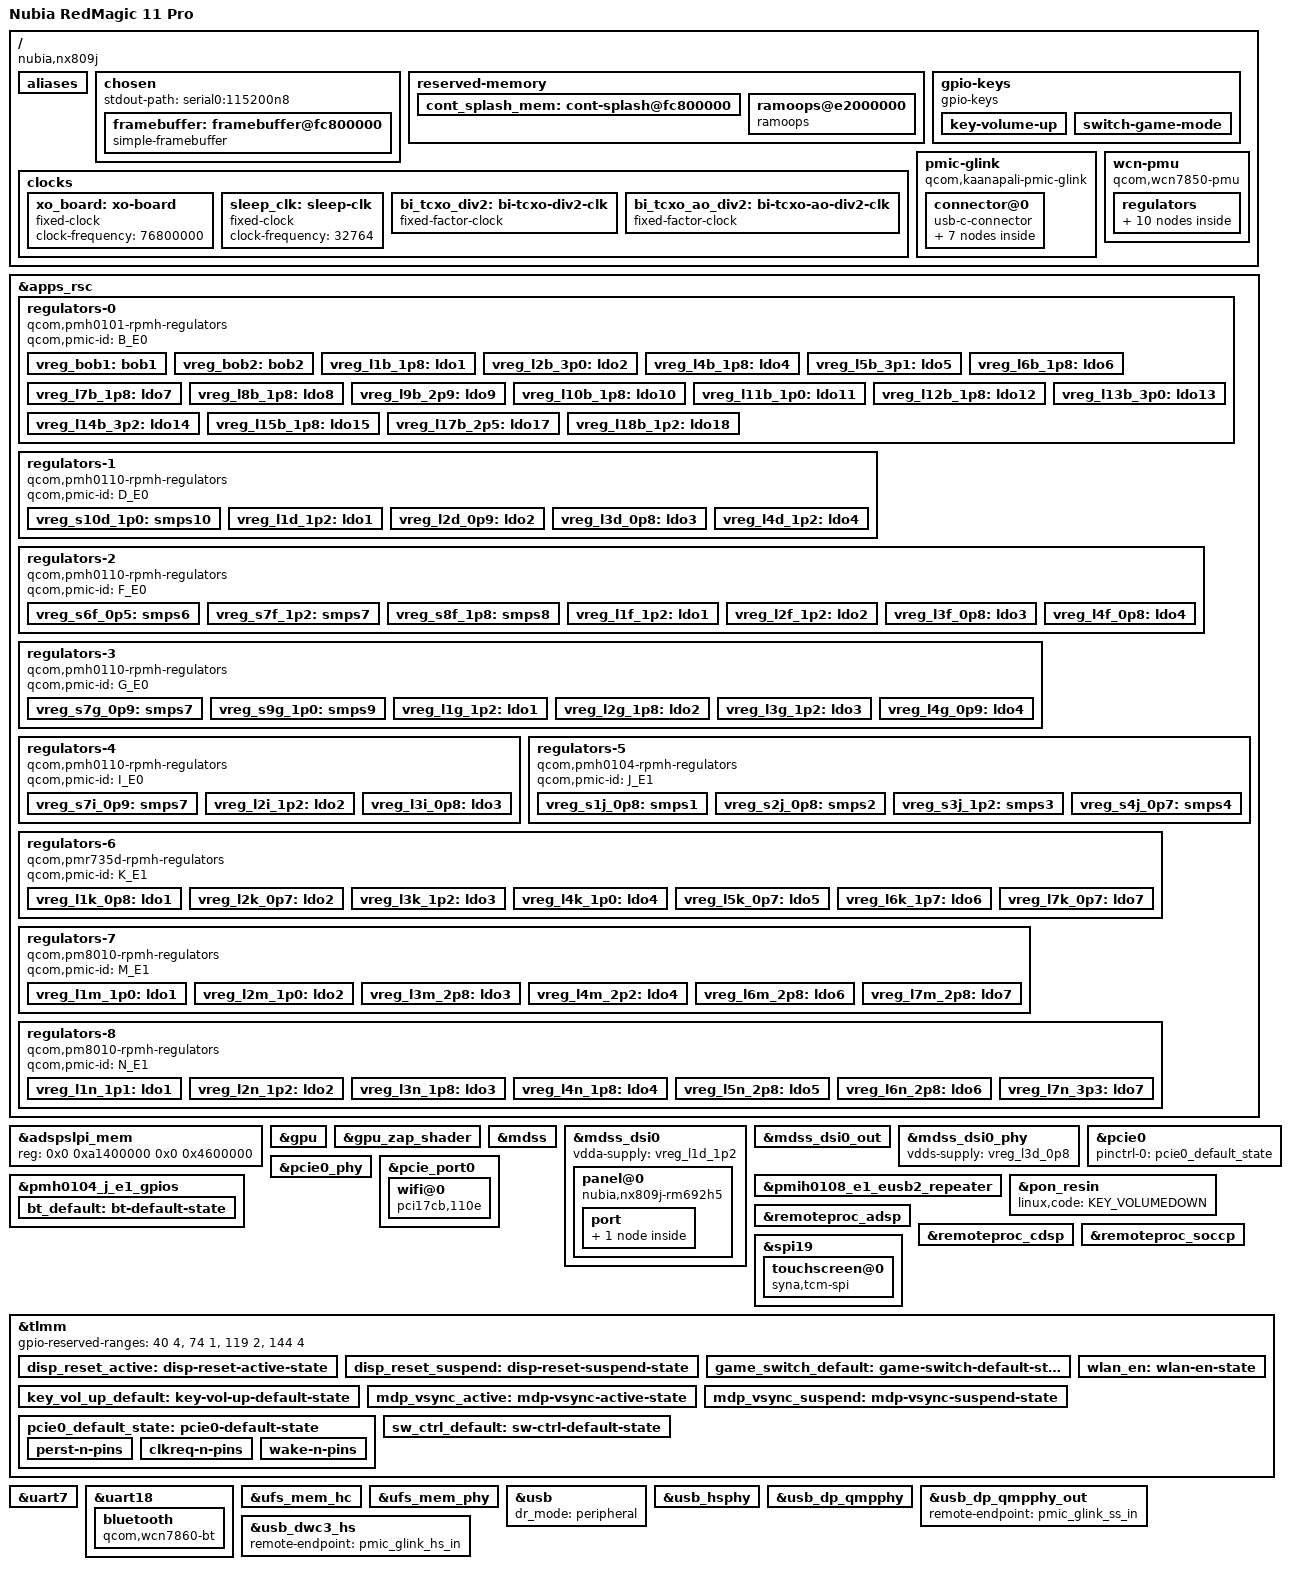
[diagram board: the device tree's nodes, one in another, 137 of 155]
// SPDX-License-Identifier: BSD-3-Clause
/*
 * Nubia RedMagic 11 Pro (NX809J), based on kaanapali-qrd.dts
 *
 * Copyright (c) Qualcomm Technologies, Inc. and/or its subsidiaries.
 */

/dts-v1/;

#include <dt-bindings/gpio/gpio.h>
#include <dt-bindings/input/linux-event-codes.h>
#include <dt-bindings/leds/common.h>
#include <dt-bindings/regulator/qcom,rpmh-regulator.h>
#include "kaanapali.dtsi"

#include "pm8010-kaanapali.dtsi"     /* SPMI1: SID-12/13   */
#include "pmd8028-kaanapali.dtsi"    /* SPMI1: SID-4       */
#include "pmh0101.dtsi"              /* SPMI0: SID-1       */
#include "pmh0104-kaanapali.dtsi"    /* SPMI1: SID-9       */
#include "pmh0110-kaanapali.dtsi"    /* SPMI0: SID-3/5/6/8 */
#include "pmih0108-kaanapali.dtsi"   /* SPMI1: SID-7       */
#include "pmk8850.dtsi"              /* SPMI0: SID-0       */
#include "pmr735d-kaanapali.dtsi"    /* SPMI1: SID-10      */

/ {
	model = "Nubia RedMagic 11 Pro";
	compatible = "nubia,nx809j", "qcom,kaanapali";
	chassis-type = "handset";

	/* Needed by the stock ABL to pick this DTB (soc 660 v2.0, MTP board) */
	qcom,msm-id = <660 0x20000>;
	qcom,board-id = <8 0>;

	aliases {
		serial0 = &uart7;
		serial1 = &uart18;
	};

	chosen {
		#address-cells = <2>;
		#size-cells = <2>;
		ranges;

		stdout-path = "serial0:115200n8";

		/* Bootloader splash, left running by ABL (BF375 RM692H5, DSC cmd mode) */
		framebuffer: framebuffer@fc800000 {
			compatible = "simple-framebuffer";
			reg = <0x0 0xfc800000 0x0 (1216 * 2688 * 4)>;
			width = <1216>;
			height = <2688>;
			stride = <(1216 * 4)>;
			format = "a8r8g8b8";
		};
	};

	reserved-memory {
		#address-cells = <2>;
		#size-cells = <2>;
		ranges;

		cont_splash_mem: cont-splash@fc800000 {
			reg = <0x0 0xfc800000 0x0 0x2b00000>;
			no-map;
		};

		/*
		 * Same layout as downstream (incl. write-combine mem-type 0), so
		 * Android shows our log in /sys/fs/pstore. A cached mapping would
		 * lose the log in the CPU caches on a hard reset.
		 */
		ramoops@e2000000 {
			compatible = "ramoops";
			reg = <0x0 0xe2000000 0x0 0x200000>;
			console-size = <0x200000>;
			mem-type = <0>;
		};
	};

	clocks {
		xo_board: xo-board {
			compatible = "fixed-clock";
			clock-frequency = <76800000>;
			#clock-cells = <0>;
		};

		sleep_clk: sleep-clk {
			compatible = "fixed-clock";
			clock-frequency = <32764>;
			#clock-cells = <0>;
		};

		bi_tcxo_div2: bi-tcxo-div2-clk {
			compatible = "fixed-factor-clock";
			#clock-cells = <0>;

			clocks = <&rpmhcc RPMH_CXO_CLK>;
			clock-mult = <1>;
			clock-div = <2>;
		};

		bi_tcxo_ao_div2: bi-tcxo-ao-div2-clk {
			compatible = "fixed-factor-clock";
			#clock-cells = <0>;

			clocks = <&rpmhcc RPMH_CXO_CLK_A>;
			clock-mult = <1>;
			clock-div = <2>;
		};
	};

	gpio-keys {
		compatible = "gpio-keys";

		pinctrl-0 = <&key_vol_up_default>, <&game_switch_default>;
		pinctrl-names = "default";

		key-volume-up {
			label = "Volume Up";
			linux,code = <KEY_VOLUMEUP>;
			gpios = <&tlmm 101 GPIO_ACTIVE_LOW>;
			debounce-interval = <15>;
			linux,can-disable;
			wakeup-source;
		};

		/*
		 * Game mode slider. Downstream reads GPIO 97 (and its complement
		 * on GPIO 174) and reports it as SW_PEN_INSERTED for lack of a
		 * better code; kept the same for now.
		 */
		switch-game-mode {
			label = "Game Mode Switch";
			linux,input-type = <EV_SW>;
			linux,code = <SW_PEN_INSERTED>;
			gpios = <&tlmm 97 GPIO_ACTIVE_HIGH>;
			debounce-interval = <30>;
		};
	};

	pmic-glink {
		compatible = "qcom,kaanapali-pmic-glink",
			     "qcom,pmic-glink";
		#address-cells = <1>;
		#size-cells = <0>;

		connector@0 {
			compatible = "usb-c-connector";
			reg = <0>;

			power-role = "dual";
			data-role = "dual";

			ports {
				#address-cells = <1>;
				#size-cells = <0>;

				port@0 {
					reg = <0>;

					pmic_glink_hs_in: endpoint {
						remote-endpoint = <&usb_dwc3_hs>;
					};
				};

				port@1 {
					reg = <1>;

					pmic_glink_ss_in: endpoint {
						remote-endpoint = <&usb_dp_qmpphy_out>;
					};
				};

				port@2 {
					reg = <2>;

					pmic_glink_sbu: endpoint {
					};
				};
			};
		};
	};

	/*
	 * The Wi-Fi/BT combo is Qualcomm's "peach" (PCI 17cb:110e), not the
	 * MTP's WCN7850, but it is wired the same way: same enable GPIOs,
	 * supplies and RF clock (downstream qcom,cnss-peach and bt_peach).
	 */
	wcn-pmu {
		compatible = "qcom,wcn7850-pmu";

		pinctrl-0 = <&bt_default>, <&sw_ctrl_default>, <&wlan_en>;
		pinctrl-names = "default";

		bt-enable-gpios = <&pmh0104_j_e1_gpios 5 GPIO_ACTIVE_HIGH>;
		wlan-enable-gpios = <&tlmm 16 GPIO_ACTIVE_HIGH>;

		vdd-supply = <&vreg_s2j_0p8>;
		vddio-supply = <&vreg_l2g_1p8>;
		vddio1p2-supply = <&vreg_l3g_1p2>;
		vddaon-supply = <&vreg_s7g_0p9>;
		vdddig-supply = <&vreg_s1j_0p8>;
		vddrfa1p2-supply = <&vreg_s7f_1p2>;
		vddrfa1p8-supply = <&vreg_s8f_1p8>;

		clocks = <&rpmhcc RPMH_RF_CLK1>;

		regulators {
			vreg_pmu_rfa_cmn: ldo0 {
				regulator-name = "vreg_pmu_rfa_cmn";
			};

			vreg_pmu_aon_0p59: ldo1 {
				regulator-name = "vreg_pmu_aon_0p59";
			};

			vreg_pmu_wlcx_0p8: ldo2 {
				regulator-name = "vreg_pmu_wlcx_0p8";
			};

			vreg_pmu_wlmx_0p85: ldo3 {
				regulator-name = "vreg_pmu_wlmx_0p85";
			};

			vreg_pmu_btcmx_0p85: ldo4 {
				regulator-name = "vreg_pmu_btcmx_0p85";
			};

			vreg_pmu_rfa_0p8: ldo5 {
				regulator-name = "vreg_pmu_rfa_0p8";
			};

			vreg_pmu_rfa_1p2: ldo6 {
				regulator-name = "vreg_pmu_rfa_1p2";
			};

			vreg_pmu_rfa_1p8: ldo7 {
				regulator-name = "vreg_pmu_rfa_1p8";
			};

			vreg_pmu_pcie_0p9: ldo8 {
				regulator-name = "vreg_pmu_pcie_0p9";
			};

			vreg_pmu_pcie_1p8: ldo9 {
				regulator-name = "vreg_pmu_pcie_1p8";
			};
		};
	};
};

&apps_rsc {
	regulators-0 {
		compatible = "qcom,pmh0101-rpmh-regulators";
		qcom,pmic-id = "B_E0";

		vreg_bob1: bob1 {
			regulator-name = "vreg_bob1";
			regulator-min-microvolt = <3008000>;
			regulator-max-microvolt = <4000000>;
			regulator-initial-mode = <RPMH_REGULATOR_MODE_HPM>;
		};

		vreg_bob2: bob2 {
			regulator-name = "vreg_bob2";
			regulator-min-microvolt = <2704000>;
			regulator-max-microvolt = <3552000>;
			regulator-initial-mode = <RPMH_REGULATOR_MODE_HPM>;
		};

		vreg_l1b_1p8: ldo1 {
			regulator-name = "vreg_l1b_1p8";
			regulator-min-microvolt = <1800000>;
			regulator-max-microvolt = <1800000>;
			regulator-initial-mode = <RPMH_REGULATOR_MODE_AUTO>;
			regulator-allow-set-load;
			regulator-allowed-modes = <RPMH_REGULATOR_MODE_LPM
						   RPMH_REGULATOR_MODE_AUTO>;
		};

		vreg_l2b_3p0: ldo2 {
			regulator-name = "vreg_l2b_3p0";
			regulator-min-microvolt = <3008000>;
			regulator-max-microvolt = <3048000>;
			regulator-initial-mode = <RPMH_REGULATOR_MODE_AUTO>;
			regulator-allow-set-load;
			regulator-allowed-modes = <RPMH_REGULATOR_MODE_LPM
						   RPMH_REGULATOR_MODE_AUTO>;
		};

		vreg_l4b_1p8: ldo4 {
			regulator-name = "vreg_l4b_1p8";
			regulator-min-microvolt = <1800000>;
			regulator-max-microvolt = <1800000>;
			regulator-initial-mode = <RPMH_REGULATOR_MODE_AUTO>;
			regulator-allow-set-load;
			regulator-allowed-modes = <RPMH_REGULATOR_MODE_LPM
						   RPMH_REGULATOR_MODE_AUTO>;
		};

		vreg_l5b_3p1: ldo5 {
			regulator-name = "vreg_l5b_3p1";
			regulator-min-microvolt = <3100000>;
			regulator-max-microvolt = <3148000>;
			regulator-initial-mode = <RPMH_REGULATOR_MODE_AUTO>;
			regulator-allow-set-load;
			regulator-allowed-modes = <RPMH_REGULATOR_MODE_LPM
						   RPMH_REGULATOR_MODE_AUTO>;
		};

		vreg_l6b_1p8: ldo6 {
			regulator-name = "vreg_l6b_1p8";
			regulator-min-microvolt = <1800000>;
			regulator-max-microvolt = <3008000>;
			regulator-initial-mode = <RPMH_REGULATOR_MODE_AUTO>;
			regulator-allow-set-load;
			regulator-allowed-modes = <RPMH_REGULATOR_MODE_LPM
						   RPMH_REGULATOR_MODE_AUTO>;
		};

		vreg_l7b_1p8: ldo7 {
			regulator-name = "vreg_l7b_1p8";
			regulator-min-microvolt = <1800000>;
			regulator-max-microvolt = <3008000>;
			regulator-initial-mode = <RPMH_REGULATOR_MODE_AUTO>;
			regulator-allow-set-load;
			regulator-allowed-modes = <RPMH_REGULATOR_MODE_LPM
						   RPMH_REGULATOR_MODE_AUTO>;
		};

		vreg_l8b_1p8: ldo8 {
			regulator-name = "vreg_l8b_1p8";
			regulator-min-microvolt = <1800000>;
			regulator-max-microvolt = <3300000>;
			regulator-initial-mode = <RPMH_REGULATOR_MODE_AUTO>;
			regulator-allow-set-load;
			regulator-allowed-modes = <RPMH_REGULATOR_MODE_LPM
						   RPMH_REGULATOR_MODE_AUTO>;
		};

		vreg_l9b_2p9: ldo9 {
			regulator-name = "vreg_l9b_2p9";
			regulator-min-microvolt = <2960000>;
			regulator-max-microvolt = <3008000>;
			regulator-initial-mode = <RPMH_REGULATOR_MODE_HPM>;
			regulator-allow-set-load;
			regulator-allowed-modes = <RPMH_REGULATOR_MODE_LPM
						   RPMH_REGULATOR_MODE_HPM>;
		};

		vreg_l10b_1p8: ldo10 {
			regulator-name = "vreg_l10b_1p8";
			regulator-min-microvolt = <1800000>;
			regulator-max-microvolt = <1800000>;
			regulator-initial-mode = <RPMH_REGULATOR_MODE_AUTO>;
			regulator-allow-set-load;
			regulator-allowed-modes = <RPMH_REGULATOR_MODE_LPM
						   RPMH_REGULATOR_MODE_AUTO>;
		};

		vreg_l11b_1p0: ldo11 {
			regulator-name = "vreg_l11b_1p0";
			regulator-min-microvolt = <1000000>;
			regulator-max-microvolt = <1292000>;
			regulator-initial-mode = <RPMH_REGULATOR_MODE_AUTO>;
			regulator-allow-set-load;
			regulator-allowed-modes = <RPMH_REGULATOR_MODE_LPM
						   RPMH_REGULATOR_MODE_AUTO>;
		};

		vreg_l12b_1p8: ldo12 {
			regulator-name = "vreg_l12b_1p8";
			regulator-min-microvolt = <1200000>;
			regulator-max-microvolt = <1800000>;
			regulator-initial-mode = <RPMH_REGULATOR_MODE_AUTO>;
			regulator-allow-set-load;
			regulator-allowed-modes = <RPMH_REGULATOR_MODE_LPM
						   RPMH_REGULATOR_MODE_AUTO>;
		};

		vreg_l13b_3p0: ldo13 {
			regulator-name = "vreg_l13b_3p0";
			regulator-min-microvolt = <3000000>;
			regulator-max-microvolt = <3000000>;
			regulator-initial-mode = <RPMH_REGULATOR_MODE_AUTO>;
			regulator-allow-set-load;
			regulator-allowed-modes = <RPMH_REGULATOR_MODE_LPM
						   RPMH_REGULATOR_MODE_AUTO>;
		};

		vreg_l14b_3p2: ldo14 {
			regulator-name = "vreg_l14b_3p2";
			regulator-min-microvolt = <3200000>;
			regulator-max-microvolt = <3200000>;
			regulator-initial-mode = <RPMH_REGULATOR_MODE_AUTO>;
			regulator-allow-set-load;
			regulator-allowed-modes = <RPMH_REGULATOR_MODE_LPM
						   RPMH_REGULATOR_MODE_AUTO>;
		};

		vreg_l15b_1p8: ldo15 {
			regulator-name = "vreg_l15b_1p8";
			regulator-min-microvolt = <1800000>;
			regulator-max-microvolt = <1800000>;
			regulator-initial-mode = <RPMH_REGULATOR_MODE_AUTO>;
			regulator-allow-set-load;
			regulator-allowed-modes = <RPMH_REGULATOR_MODE_LPM
						   RPMH_REGULATOR_MODE_AUTO>;
		};

		vreg_l17b_2p5: ldo17 {
			regulator-name = "vreg_l17b_2p5";
			regulator-min-microvolt = <2504000>;
			regulator-max-microvolt = <2504000>;
			regulator-initial-mode = <RPMH_REGULATOR_MODE_HPM>;
			regulator-allow-set-load;
			regulator-allowed-modes = <RPMH_REGULATOR_MODE_LPM
						   RPMH_REGULATOR_MODE_HPM>;
		};

		vreg_l18b_1p2: ldo18 {
			regulator-name = "vreg_l18b_1p2";
			regulator-min-microvolt = <1200000>;
			regulator-max-microvolt = <1200000>;
			regulator-initial-mode = <RPMH_REGULATOR_MODE_AUTO>;
			regulator-allow-set-load;
			regulator-allowed-modes = <RPMH_REGULATOR_MODE_LPM
						   RPMH_REGULATOR_MODE_AUTO>;
		};
	};

	regulators-1 {
		compatible = "qcom,pmh0110-rpmh-regulators";
		qcom,pmic-id = "D_E0";

		vreg_s10d_1p0: smps10 {
			regulator-name = "vreg_s10d_1p0";
			regulator-min-microvolt = <1000000>;
			regulator-max-microvolt = <1100000>;
			regulator-initial-mode = <RPMH_REGULATOR_MODE_HPM>;
		};

		vreg_l1d_1p2: ldo1 {
			regulator-name = "vreg_l1d_1p2";
			regulator-min-microvolt = <1200000>;
			regulator-max-microvolt = <1256000>;
			regulator-initial-mode = <RPMH_REGULATOR_MODE_AUTO>;
			regulator-allow-set-load;
			regulator-allowed-modes = <RPMH_REGULATOR_MODE_LPM
						   RPMH_REGULATOR_MODE_AUTO>;
		};

		vreg_l2d_0p9: ldo2 {
			regulator-name = "vreg_l2d_0p9";
			regulator-min-microvolt = <912000>;
			regulator-max-microvolt = <958000>;
			regulator-initial-mode = <RPMH_REGULATOR_MODE_AUTO>;
			regulator-allow-set-load;
			regulator-allowed-modes = <RPMH_REGULATOR_MODE_LPM
						   RPMH_REGULATOR_MODE_AUTO>;
		};

		vreg_l3d_0p8: ldo3 {
			regulator-name = "vreg_l3d_0p8";
			regulator-min-microvolt = <880000>;
			regulator-max-microvolt = <880000>;
			regulator-initial-mode = <RPMH_REGULATOR_MODE_AUTO>;
			regulator-allow-set-load;
			regulator-allowed-modes = <RPMH_REGULATOR_MODE_LPM
						   RPMH_REGULATOR_MODE_AUTO>;
		};

		vreg_l4d_1p2: ldo4 {
			regulator-name = "vreg_l4d_1p2";
			regulator-min-microvolt = <1200000>;
			regulator-max-microvolt = <1200000>;
			regulator-initial-mode = <RPMH_REGULATOR_MODE_AUTO>;
			regulator-allow-set-load;
			regulator-allowed-modes = <RPMH_REGULATOR_MODE_LPM
						   RPMH_REGULATOR_MODE_AUTO>;
		};
	};

	regulators-2 {
		compatible = "qcom,pmh0110-rpmh-regulators";
		qcom,pmic-id = "F_E0";

		vreg_s6f_0p5: smps6 {
			regulator-name = "vreg_s6f_0p5";
			regulator-min-microvolt = <300000>;
			regulator-max-microvolt = <570000>;
			regulator-initial-mode = <RPMH_REGULATOR_MODE_HPM>;
		};

		/*
		 * S7F/S8F feed the Wi-Fi/BT chip's RF (and PCIe) rails. As for
		 * S1J/S2J, nothing sets their voltage: use downstream cnss2's
		 * vdd-wlan-rfa2/rfa1 floors, 1.328 V and 1.876 V.
		 */
		vreg_s7f_1p2: smps7 {
			regulator-name = "vreg_s7f_1p2";
			regulator-min-microvolt = <1328000>;
			regulator-max-microvolt = <1372000>;
			regulator-initial-mode = <RPMH_REGULATOR_MODE_HPM>;
		};

		vreg_s8f_1p8: smps8 {
			regulator-name = "vreg_s8f_1p8";
			regulator-min-microvolt = <1876000>;
			regulator-max-microvolt = <2000000>;
			regulator-initial-mode = <RPMH_REGULATOR_MODE_HPM>;
		};

		vreg_l1f_1p2: ldo1 {
			regulator-name = "vreg_l1f_1p2";
			regulator-min-microvolt = <1200000>;
			regulator-max-microvolt = <1200000>;
			regulator-initial-mode = <RPMH_REGULATOR_MODE_AUTO>;
			regulator-allow-set-load;
			regulator-allowed-modes = <RPMH_REGULATOR_MODE_LPM
						   RPMH_REGULATOR_MODE_AUTO>;
		};

		vreg_l2f_1p2: ldo2 {
			regulator-name = "vreg_l2f_1p2";
			regulator-min-microvolt = <1200000>;
			regulator-max-microvolt = <1200000>;
			regulator-initial-mode = <RPMH_REGULATOR_MODE_AUTO>;
			regulator-allow-set-load;
			regulator-allowed-modes = <RPMH_REGULATOR_MODE_LPM
						   RPMH_REGULATOR_MODE_AUTO>;
		};

		vreg_l3f_0p8: ldo3 {
			regulator-name = "vreg_l3f_0p8";
			regulator-min-microvolt = <880000>;
			regulator-max-microvolt = <936000>;
			regulator-initial-mode = <RPMH_REGULATOR_MODE_AUTO>;
			regulator-allow-set-load;
			regulator-allowed-modes = <RPMH_REGULATOR_MODE_LPM
						   RPMH_REGULATOR_MODE_AUTO>;
		};

		vreg_l4f_0p8: ldo4 {
			regulator-name = "vreg_l4f_0p8";
			regulator-min-microvolt = <880000>;
			regulator-max-microvolt = <912000>;
			regulator-initial-mode = <RPMH_REGULATOR_MODE_AUTO>;
			regulator-allow-set-load;
			regulator-allowed-modes = <RPMH_REGULATOR_MODE_LPM
						   RPMH_REGULATOR_MODE_AUTO>;
		};
	};

	regulators-3 {
		compatible = "qcom,pmh0110-rpmh-regulators";
		qcom,pmic-id = "G_E0";

		vreg_s7g_0p9: smps7 {
			regulator-name = "vreg_s7g_0p9";
			regulator-min-microvolt = <880000>;
			regulator-max-microvolt = <1100000>;
			regulator-initial-mode = <RPMH_REGULATOR_MODE_HPM>;
		};

		vreg_s9g_1p0: smps9 {
			regulator-name = "vreg_s9g_1p0";
			regulator-min-microvolt = <1000000>;
			regulator-max-microvolt = <1100000>;
			regulator-initial-mode = <RPMH_REGULATOR_MODE_HPM>;
		};

		vreg_l1g_1p2: ldo1 {
			regulator-name = "vreg_l1g_1p2";
			regulator-min-microvolt = <1200000>;
			regulator-max-microvolt = <1200000>;
			regulator-initial-mode = <RPMH_REGULATOR_MODE_AUTO>;
			regulator-allow-set-load;
			regulator-allowed-modes = <RPMH_REGULATOR_MODE_LPM
						   RPMH_REGULATOR_MODE_AUTO>;
		};

		vreg_l2g_1p8: ldo2 {
			regulator-name = "vreg_l2g_1p8";
			regulator-min-microvolt = <1800000>;
			regulator-max-microvolt = <1800000>;
			regulator-initial-mode = <RPMH_REGULATOR_MODE_AUTO>;
			regulator-allow-set-load;
			regulator-allowed-modes = <RPMH_REGULATOR_MODE_LPM
						   RPMH_REGULATOR_MODE_AUTO>;
		};

		vreg_l3g_1p2: ldo3 {
			regulator-name = "vreg_l3g_1p2";
			regulator-min-microvolt = <1200000>;
			regulator-max-microvolt = <1200000>;
			regulator-initial-mode = <RPMH_REGULATOR_MODE_AUTO>;
			regulator-allow-set-load;
			regulator-allowed-modes = <RPMH_REGULATOR_MODE_LPM
						   RPMH_REGULATOR_MODE_AUTO>;
		};

		vreg_l4g_0p9: ldo4 {
			regulator-name = "vreg_l4g_0p9";
			regulator-min-microvolt = <912000>;
			regulator-max-microvolt = <912000>;
			regulator-initial-mode = <RPMH_REGULATOR_MODE_AUTO>;
			regulator-allow-set-load;
			regulator-allowed-modes = <RPMH_REGULATOR_MODE_LPM
						   RPMH_REGULATOR_MODE_AUTO>;
		};
	};

	regulators-4 {
		compatible = "qcom,pmh0110-rpmh-regulators";
		qcom,pmic-id = "I_E0";

		vreg_s7i_0p9: smps7 {
			regulator-name = "vreg_s7i_0p9";
			regulator-min-microvolt = <900000>;
			regulator-max-microvolt = <972000>;
			regulator-initial-mode = <RPMH_REGULATOR_MODE_HPM>;
		};

		vreg_l2i_1p2: ldo2 {
			regulator-name = "vreg_l2i_1p2";
			regulator-min-microvolt = <1200000>;
			regulator-max-microvolt = <1200000>;
			regulator-initial-mode = <RPMH_REGULATOR_MODE_AUTO>;
			regulator-allow-set-load;
			regulator-allowed-modes = <RPMH_REGULATOR_MODE_LPM
						   RPMH_REGULATOR_MODE_AUTO>;
		};

		vreg_l3i_0p8: ldo3 {
			regulator-name = "vreg_l3i_0p8";
			regulator-min-microvolt = <880000>;
			regulator-max-microvolt = <920000>;
			regulator-initial-mode = <RPMH_REGULATOR_MODE_AUTO>;
			regulator-allow-set-load;
			regulator-allowed-modes = <RPMH_REGULATOR_MODE_LPM
						   RPMH_REGULATOR_MODE_AUTO>;
		};
	};

	regulators-5 {
		compatible = "qcom,pmh0104-rpmh-regulators";
		qcom,pmic-id = "J_E1";

		/*
		 * S1J/S2J are the Wi-Fi/BT chip's CX and digital rails. Nothing
		 * sets their voltage, so the floor is what gets voted: keep it at
		 * downstream cnss2's 0.892 V, firmware crashes when started lower.
		 */
		vreg_s1j_0p8: smps1 {
			regulator-name = "vreg_s1j_0p8";
			regulator-min-microvolt = <892000>;
			regulator-max-microvolt = <1000000>;
			regulator-initial-mode = <RPMH_REGULATOR_MODE_HPM>;
		};

		vreg_s2j_0p8: smps2 {
			regulator-name = "vreg_s2j_0p8";
			regulator-min-microvolt = <892000>;
			regulator-max-microvolt = <1000000>;
			regulator-initial-mode = <RPMH_REGULATOR_MODE_HPM>;
		};

		vreg_s3j_1p2: smps3 {
			regulator-name = "vreg_s3j_1p2";
			regulator-min-microvolt = <1200000>;
			regulator-max-microvolt = <1300000>;
			regulator-initial-mode = <RPMH_REGULATOR_MODE_HPM>;
		};

		vreg_s4j_0p7: smps4 {
			regulator-name = "vreg_s4j_0p7";
			regulator-min-microvolt = <300000>;
			regulator-max-microvolt = <1000000>;
			regulator-initial-mode = <RPMH_REGULATOR_MODE_HPM>;
		};
	};

	regulators-6 {
		compatible = "qcom,pmr735d-rpmh-regulators";
		qcom,pmic-id = "K_E1";

		vreg_l1k_0p8: ldo1 {
			regulator-name = "vreg_l1k_0p8";
			regulator-min-microvolt = <300000>;
			regulator-max-microvolt = <1100000>;
			regulator-initial-mode = <RPMH_REGULATOR_MODE_HPM>;
			regulator-allow-set-load;
			regulator-allowed-modes = <RPMH_REGULATOR_MODE_LPM
						   RPMH_REGULATOR_MODE_HPM>;
		};

		vreg_l2k_0p7: ldo2 {
			regulator-name = "vreg_l2k_0p7";
			regulator-min-microvolt = <700000>;
			regulator-max-microvolt = <1000000>;
			regulator-initial-mode = <RPMH_REGULATOR_MODE_HPM>;
			regulator-allow-set-load;
			regulator-allowed-modes = <RPMH_REGULATOR_MODE_LPM
						   RPMH_REGULATOR_MODE_HPM>;
		};

		/* Wi-Fi/BT antenna sharing (downstream vdd-wlan-ant-share) */
		vreg_l3k_1p2: ldo3 {
			regulator-name = "vreg_l3k_1p2";
			regulator-min-microvolt = <1200000>;
			regulator-max-microvolt = <1200000>;
			regulator-initial-mode = <RPMH_REGULATOR_MODE_HPM>;
			regulator-always-on;
			regulator-allow-set-load;
			regulator-allowed-modes = <RPMH_REGULATOR_MODE_LPM
						   RPMH_REGULATOR_MODE_HPM>;
		};

		vreg_l4k_1p0: ldo4 {
			regulator-name = "vreg_l4k_1p0";
			regulator-min-microvolt = <1000000>;
			regulator-max-microvolt = <1200000>;
			regulator-initial-mode = <RPMH_REGULATOR_MODE_HPM>;
			regulator-allow-set-load;
			regulator-allowed-modes = <RPMH_REGULATOR_MODE_LPM
						   RPMH_REGULATOR_MODE_HPM>;
		};

		vreg_l5k_0p7: ldo5 {
			regulator-name = "vreg_l5k_0p7";
			regulator-min-microvolt = <700000>;
			regulator-max-microvolt = <1000000>;
			regulator-initial-mode = <RPMH_REGULATOR_MODE_HPM>;
			regulator-allow-set-load;
			regulator-allowed-modes = <RPMH_REGULATOR_MODE_LPM
						   RPMH_REGULATOR_MODE_HPM>;
		};

		vreg_l6k_1p7: ldo6 {
			regulator-name = "vreg_l6k_1p7";
			regulator-min-microvolt = <1700000>;
			regulator-max-microvolt = <2000000>;
			regulator-initial-mode = <RPMH_REGULATOR_MODE_HPM>;
			regulator-allow-set-load;
			regulator-allowed-modes = <RPMH_REGULATOR_MODE_LPM
						   RPMH_REGULATOR_MODE_HPM>;
		};

		vreg_l7k_0p7: ldo7 {
			regulator-name = "vreg_l7k_0p7";
			regulator-min-microvolt = <700000>;
			regulator-max-microvolt = <848000>;
			regulator-initial-mode = <RPMH_REGULATOR_MODE_HPM>;
			regulator-allow-set-load;
			regulator-allowed-modes = <RPMH_REGULATOR_MODE_LPM
						   RPMH_REGULATOR_MODE_HPM>;
		};
	};

	regulators-7 {
		compatible = "qcom,pm8010-rpmh-regulators";
		qcom,pmic-id = "M_E1";

		vreg_l1m_1p0: ldo1 {
			regulator-name = "vreg_l1m_1p0";
			regulator-min-microvolt = <1000000>;
			regulator-max-microvolt = <1200000>;
			regulator-initial-mode = <RPMH_REGULATOR_MODE_HPM>;
			regulator-allow-set-load;
			regulator-allowed-modes = <RPMH_REGULATOR_MODE_LPM
						   RPMH_REGULATOR_MODE_HPM>;
		};

		vreg_l2m_1p0: ldo2 {
			regulator-name = "vreg_l2m_1p0";
			regulator-min-microvolt = <1096000>;
			regulator-max-microvolt = <1104000>;
			regulator-initial-mode = <RPMH_REGULATOR_MODE_HPM>;
			regulator-allow-set-load;
			regulator-allowed-modes = <RPMH_REGULATOR_MODE_LPM
						   RPMH_REGULATOR_MODE_HPM>;
		};

		vreg_l3m_2p8: ldo3 {
			regulator-name = "vreg_l3m_2p8";
			regulator-min-microvolt = <2800000>;
			regulator-max-microvolt = <2900000>;
			regulator-initial-mode = <RPMH_REGULATOR_MODE_HPM>;
		};

		vreg_l4m_2p2: ldo4 {
			regulator-name = "vreg_l4m_2p2";
			regulator-min-microvolt = <2200000>;
			regulator-max-microvolt = <2800000>;
			regulator-initial-mode = <RPMH_REGULATOR_MODE_HPM>;
		};

		vreg_l6m_2p8: ldo6 {
			regulator-name = "vreg_l6m_2p8";
			regulator-min-microvolt = <2800000>;
			regulator-max-microvolt = <2800000>;
			regulator-initial-mode = <RPMH_REGULATOR_MODE_HPM>;
		};

		vreg_l7m_2p8: ldo7 {
			regulator-name = "vreg_l7m_2p8";
			/* Downstream asks 3.3 V; this LDO steps 8 mV from 1.504 V */
			regulator-min-microvolt = <3304000>;
			regulator-max-microvolt = <3304000>;
			regulator-initial-mode = <RPMH_REGULATOR_MODE_HPM>;
		};
	};

	regulators-8 {
		compatible = "qcom,pm8010-rpmh-regulators";
		qcom,pmic-id = "N_E1";

		vreg_l1n_1p1: ldo1 {
			regulator-name = "vreg_l1n_1p1";
			regulator-min-microvolt = <1096000>;
			regulator-max-microvolt = <1200000>;
			regulator-initial-mode = <RPMH_REGULATOR_MODE_HPM>;
			regulator-allow-set-load;
			regulator-allowed-modes = <RPMH_REGULATOR_MODE_LPM
						   RPMH_REGULATOR_MODE_HPM>;
		};

		vreg_l2n_1p2: ldo2 {
			regulator-name = "vreg_l2n_1p2";
			regulator-min-microvolt = <1200000>;
			regulator-max-microvolt = <1200000>;
			regulator-initial-mode = <RPMH_REGULATOR_MODE_HPM>;
			regulator-allow-set-load;
			regulator-allowed-modes = <RPMH_REGULATOR_MODE_LPM
						   RPMH_REGULATOR_MODE_HPM>;
		};

		vreg_l3n_1p8: ldo3 {
			regulator-name = "vreg_l3n_1p8";
			regulator-min-microvolt = <1800000>;
			regulator-max-microvolt = <1800000>;
			regulator-initial-mode = <RPMH_REGULATOR_MODE_HPM>;
		};

		vreg_l4n_1p8: ldo4 {
			regulator-name = "vreg_l4n_1p8";
			regulator-min-microvolt = <1800000>;
			regulator-max-microvolt = <1800000>;
			regulator-initial-mode = <RPMH_REGULATOR_MODE_HPM>;
		};

		vreg_l5n_2p8: ldo5 {
			regulator-name = "vreg_l5n_2p8";
			regulator-min-microvolt = <2800000>;
			regulator-max-microvolt = <2800000>;
			regulator-initial-mode = <RPMH_REGULATOR_MODE_HPM>;
		};

		vreg_l6n_2p8: ldo6 {
			regulator-name = "vreg_l6n_2p8";
			regulator-min-microvolt = <2800000>;
			regulator-max-microvolt = <2800000>;
			regulator-initial-mode = <RPMH_REGULATOR_MODE_HPM>;
		};

		vreg_l7n_3p3: ldo7 {
			regulator-name = "vreg_l7n_3p3";
			regulator-min-microvolt = <3304000>;
			regulator-max-microvolt = <3304000>;
			regulator-initial-mode = <RPMH_REGULATOR_MODE_HPM>;
		};
	};
};

/* Downstream carve-out is 70 MiB here, not 76 MiB; the rest is plain RAM */
&adspslpi_mem {
	reg = <0x0 0xa1400000 0x0 0x4600000>;
};

&gpu {
	status = "okay";
};

&gpu_zap_shader {
	firmware-name = "qcom/kaanapali/nubia/nx809j/gen80200_zap.mbn";
};

&mdss {
	status = "okay";
};

&mdss_dsi0 {
	vdda-supply = <&vreg_l1d_1p2>;

	status = "okay";

	panel@0 {
		compatible = "nubia,nx809j-rm692h5", "raydium,rm692h5";
		reg = <0>;

		pinctrl-0 = <&disp_reset_active &mdp_vsync_active>;
		pinctrl-1 = <&disp_reset_suspend &mdp_vsync_suspend>;
		pinctrl-names = "default", "sleep";

		vddio-supply = <&vreg_l12b_1p8>;
		vdd-supply = <&vreg_l11b_1p0>;
		vci-supply = <&vreg_l13b_3p0>;

		reset-gpios = <&tlmm 98 GPIO_ACTIVE_LOW>;

		port {
			panel0_in: endpoint {
				remote-endpoint = <&mdss_dsi0_out>;
			};
		};
	};
};

&mdss_dsi0_out {
	remote-endpoint = <&panel0_in>;
	data-lanes = <0 1 2 3>;
};

&mdss_dsi0_phy {
	vdds-supply = <&vreg_l3d_0p8>;

	status = "okay";
};

&pcie0 {
	pinctrl-0 = <&pcie0_default_state>;
	pinctrl-names = "default";

	status = "okay";
};

&pcie0_phy {
	vdda-phy-supply = <&vreg_l3i_0p8>;
	vdda-pll-supply = <&vreg_l1d_1p2>;

	status = "okay";
};

&pcie_port0 {
	wake-gpios = <&tlmm 104 GPIO_ACTIVE_LOW>;
	reset-gpios = <&tlmm 102 GPIO_ACTIVE_LOW>;

	wifi@0 {
		compatible = "pci17cb,110e";
		reg = <0x10000 0x0 0x0 0x0 0x0>;

		vddrfacmn-supply = <&vreg_pmu_rfa_cmn>;
		vddaon-supply = <&vreg_pmu_aon_0p59>;
		vddwlcx-supply = <&vreg_pmu_wlcx_0p8>;
		vddwlmx-supply = <&vreg_pmu_wlmx_0p85>;
		vddrfa0p8-supply = <&vreg_pmu_rfa_0p8>;
		vddrfa1p2-supply = <&vreg_pmu_rfa_1p2>;
		vddrfa1p8-supply = <&vreg_pmu_rfa_1p8>;
		vddpcie0p9-supply = <&vreg_pmu_pcie_0p9>;
		vddpcie1p8-supply = <&vreg_pmu_pcie_1p8>;
	};
};

&pmh0104_j_e1_gpios {
	bt_default: bt-default-state {
		pins = "gpio5";
		function = "normal";
		input-disable;
		output-enable;
		output-low;
		bias-disable;
		power-source = <1>;
	};
};

&pmih0108_e1_eusb2_repeater {
	vdd18-supply = <&vreg_l15b_1p8>;
	vdd3-supply = <&vreg_l5b_3p1>;
};

&pon_resin {
	linux,code = <KEY_VOLUMEDOWN>;

	status = "okay";
};

&remoteproc_adsp {
	firmware-name = "qcom/kaanapali/nubia/nx809j/adsp.mbn",
			"qcom/kaanapali/nubia/nx809j/adsp_dtb.mbn";

	status = "okay";
};

&remoteproc_cdsp {
	firmware-name = "qcom/kaanapali/nubia/nx809j/cdsp.mbn",
			"qcom/kaanapali/nubia/nx809j/cdsp_dtb.mbn";
};

&remoteproc_soccp {
	firmware-name = "qcom/kaanapali/nubia/nx809j/soccp.mbn",
			"qcom/kaanapali/nubia/nx809j/soccp_dtb.mbn";
};

&spi19 {
	status = "okay";

	/* Synaptics TouchComm controller; wiring from the downstream DT */
	touchscreen@0 {
		compatible = "syna,tcm-spi";
		reg = <0>;
		spi-max-frequency = <10000000>;

		interrupts-extended = <&tlmm 158 IRQ_TYPE_LEVEL_LOW>;
		reset-gpios = <&tlmm 66 GPIO_ACTIVE_LOW>;

		vdd-supply = <&vreg_l4b_1p8>;
		avdd-supply = <&vreg_l14b_3p2>;
	};
};

&tlmm {
	/* From qcom,gpios-reserved in the downstream DT */
	gpio-reserved-ranges = <40 4>, /* NFC eSE SPI */
			       <74 1>, /* eSE */
			       <119 2>, /* SoCCP */
			       <144 4>; /* CXM UART */

	disp_reset_active: disp-reset-active-state {
		pins = "gpio98";
		function = "gpio";
		drive-strength = <8>;
		bias-disable;
	};

	disp_reset_suspend: disp-reset-suspend-state {
		pins = "gpio98";
		function = "gpio";
		drive-strength = <2>;
		bias-pull-down;
	};

	game_switch_default: game-switch-default-state {
		pins = "gpio97";
		function = "gpio";
		output-disable;
		bias-disable;
	};

	key_vol_up_default: key-vol-up-default-state {
		pins = "gpio101";
		function = "gpio";
		output-disable;
		bias-pull-up;
	};

	mdp_vsync_active: mdp-vsync-active-state {
		pins = "gpio86";
		function = "mdp_vsync";
		drive-strength = <2>;
		bias-pull-down;
	};

	mdp_vsync_suspend: mdp-vsync-suspend-state {
		pins = "gpio86";
		function = "mdp_vsync";
		drive-strength = <2>;
		bias-pull-down;
	};

	pcie0_default_state: pcie0-default-state {
		perst-n-pins {
			pins = "gpio102";
			function = "gpio";
			drive-strength = <2>;
			bias-disable;
		};

		clkreq-n-pins {
			pins = "gpio103";
			function = "pcie0_clk_req_n";
			drive-strength = <2>;
			bias-pull-up;
		};

		wake-n-pins {
			pins = "gpio104";
			function = "gpio";
			drive-strength = <2>;
			bias-pull-up;
		};
	};

	sw_ctrl_default: sw-ctrl-default-state {
		pins = "gpio18";
		function = "gpio";
		bias-pull-down;
	};

	wlan_en: wlan-en-state {
		pins = "gpio16";
		function = "gpio";
		drive-strength = <8>;
		bias-pull-down;
	};
};

&uart7 {
	status = "okay";
};

&uart18 {
	status = "okay";

	/* Bluetooth half of the peach combo: a WCN7860-style Brahma controller */
	bluetooth {
		compatible = "qcom,wcn7860-bt";

		vddrfacmn-supply = <&vreg_pmu_rfa_cmn>;
		vddaon-supply = <&vreg_pmu_aon_0p59>;
		vddwlcx-supply = <&vreg_pmu_wlcx_0p8>;
		vddwlmx-supply = <&vreg_pmu_wlmx_0p85>;
		vddrfa0p8-supply = <&vreg_pmu_rfa_0p8>;
		vddrfa1p2-supply = <&vreg_pmu_rfa_1p2>;
		vddrfa1p8-supply = <&vreg_pmu_rfa_1p8>;

		max-speed = <3200000>;
	};
};


&ufs_mem_hc {
	reset-gpios = <&tlmm 217 GPIO_ACTIVE_LOW>;

	vcc-supply = <&vreg_l17b_2p5>;
	vcc-max-microamp = <1200000>;
	vccq-supply = <&vreg_l4d_1p2>;
	vccq-max-microamp = <1200000>;

	status = "okay";
};

&ufs_mem_phy {
	vdda-phy-supply = <&vreg_l4g_0p9>;
	vdda-pll-supply = <&vreg_l1d_1p2>;

	status = "okay";
};

&usb {
	/*
	 * The role normally comes from pmic-glink, which needs the ADSP.
	 * Until that runs, force device mode for the USB network shell.
	 */
	dr_mode = "peripheral";
	/delete-property/ usb-role-switch;

	status = "okay";
};

&usb_hsphy {
	vdd-supply = <&vreg_l4f_0p8>;
	vdda12-supply = <&vreg_l1d_1p2>;

	phys = <&pmih0108_e1_eusb2_repeater>;

	status = "okay";
};

&usb_dp_qmpphy {
	vdda-phy-supply = <&vreg_l4f_0p8>;
	vdda-pll-supply = <&vreg_l1d_1p2>;

	status = "okay";
};

&usb_dp_qmpphy_out {
	remote-endpoint = <&pmic_glink_ss_in>;
};

&usb_dwc3_hs {
	remote-endpoint = <&pmic_glink_hs_in>;
};
